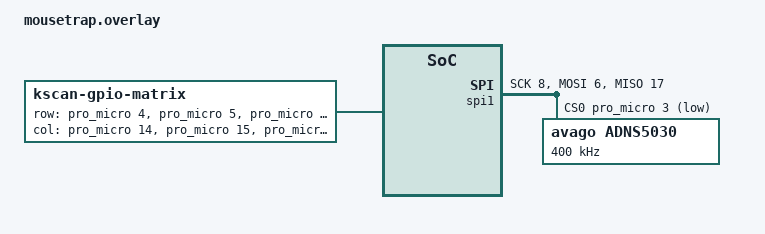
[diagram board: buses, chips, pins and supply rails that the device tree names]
/*
 * Copyright (c) 2020 Pete Johanson, Richard Jones
 *
 * SPDX-License-Identifier: MIT
 */

#include <dt-bindings/zmk/matrix_transform.h>

/ {
	chosen {
		zmk,kscan = &kscan0;
		zmk,mouse = &mysensor;
	};

	kscan0: kscan {
		compatible = "zmk,kscan-gpio-matrix";
		label = "KSCAN";

		diode-direction = "col2row";
		row-gpios
			= <&pro_micro 4 (GPIO_ACTIVE_HIGH | GPIO_PULL_DOWN)>
			, <&pro_micro 5 (GPIO_ACTIVE_HIGH | GPIO_PULL_DOWN)>
			, <&pro_micro 6 (GPIO_ACTIVE_HIGH | GPIO_PULL_DOWN)>
			, <&pro_micro 7 (GPIO_ACTIVE_HIGH | GPIO_PULL_DOWN)>
			;

		col-gpios
			= <&pro_micro 14 GPIO_ACTIVE_HIGH>
			, <&pro_micro 15 GPIO_ACTIVE_HIGH>
			, <&pro_micro 18 GPIO_ACTIVE_HIGH>
			, <&pro_micro 19 GPIO_ACTIVE_HIGH>
			, <&pro_micro 20 GPIO_ACTIVE_HIGH>
			;

	};
};


&spi1 {
	compatible = "nordic,nrf-spim";
	status = "okay";
	mosi-pin = <6>;  // P0.06 = D1
	sck-pin = <8>;   // P0.08 = D0
	miso-pin = <17>; // P0.17 = D2
	cs-gpios = <&pro_micro 3 GPIO_ACTIVE_LOW>;

	mysensor: adns5030@0 {
		compatible = "avago,adns5030";
		label = "adns5030";
		reg = <0>;
		spi-max-frequency = <400000>;
	};
};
